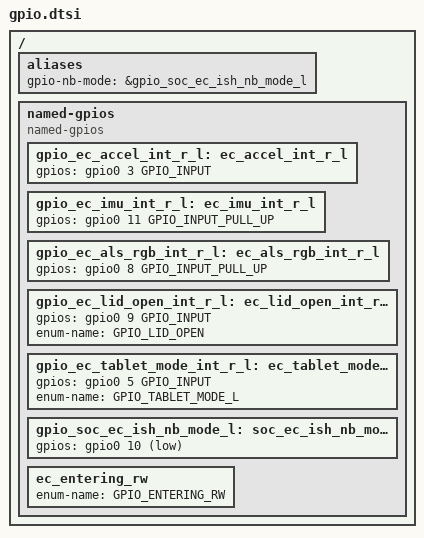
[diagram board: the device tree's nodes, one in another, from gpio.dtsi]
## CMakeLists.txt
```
# Copyright 2023 The ChromiumOS Authors
# Use of this source code is governed by a BSD-style license that can be
# found in the LICENSE file.

zephyr_library_sources("src/board_nb_mode.c")
```

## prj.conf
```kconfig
# Copyright 2023 The ChromiumOS Authors
# Use of this source code is governed by a BSD-style license that can be
# found in the LICENSE file.

# Fix compile issue
CONFIG_CROS_EC_RAM_BASE=0xff216900
CONFIG_CROS_EC_RAM_SIZE=0x00015000
CONFIG_CROS_EC_DATA_RAM_SIZE=0x00010000
CONFIG_CROS_EC_PROGRAM_MEMORY_BASE=0x10090000
CONFIG_CROS_EC_RO_MEM_OFF=0x0
CONFIG_CROS_EC_RO_SIZE=0xb000
CONFIG_CROS_EC_RW_MEM_OFF=0xb000
CONFIG_CROS_EC_RW_SIZE=0x75000

CONFIG_PLATFORM_EC=y
CONFIG_CROS_EC=y
CONFIG_SHIMMED_TASKS=y
CONFIG_SYSCON=y

# Disable default features
CONFIG_BOARD_REX_USBC_CONFIG=n

# Log
CONFIG_LOG=y
CONFIG_LOG_MODE_MINIMAL=y

# Host Interface and  MKBP event
CONFIG_PLATFORM_EC_HOST_INTERFACE_HECI=y
CONFIG_PLATFORM_EC_MKBP_EVENT=y
CONFIG_PLATFORM_EC_MKBP_USE_HECI=y

# ISH BSP config
CONFIG_IPM=y
CONFIG_HECI=y
CONFIG_HOST_SERVICE=y
CONFIG_HECI_INTF_IPM=y
CONFIG_REBOOT=y
CONFIG_SPI=n
CONFIG_GPIO=y

#ISH PM
CONFIG_PM=y
CONFIG_PM_DEVICE=y
CONFIG_PM_DEVICE_RUNTIME=n
CONFIG_GDT_DYNAMIC=y
CONFIG_GDT_RESERVED_NUM_ENTRIES=3
CONFIG_PLATFORM_EC_CONSOLE_CMD_SLEEPMASK=n

# Other
CONFIG_SHELL_PROMPT_UART="ish:~$ "
CONFIG_SHELL_BACKEND_SERIAL_INTERRUPT_DRIVEN=n
CONFIG_SHELL_BACKEND_SERIAL_RX_POLL_PERIOD=60000

# Sensor Console Commands
CONFIG_PLATFORM_EC_CONSOLE_CMD_ACCELS=y
CONFIG_PLATFORM_EC_CONSOLE_CMD_ACCEL_INFO=y
CONFIG_PLATFORM_EC_CONSOLE_CMD_I2C_SPEED=y

# Sensor Feature Configs
CONFIG_PLATFORM_EC_ACCEL_FIFO=y
CONFIG_PLATFORM_EC_DYNAMIC_MOTION_SENSOR_COUNT=y
CONFIG_PLATFORM_EC_LID_ANGLE=y
CONFIG_PLATFORM_EC_LID_ANGLE_UPDATE=y
CONFIG_PLATFORM_EC_SENSOR_TIGHT_TIMESTAMPS=y
CONFIG_PLATFORM_EC_GMR_TABLET_MODE=y
CONFIG_PLATFORM_EC_TABLET_MODE=y
CONFIG_PLATFORM_EC_TABLET_MODE_SWITCH=y
CONFIG_PLATFORM_EC_LID_SWITCH=y

# Sensor Drivers
CONFIG_PLATFORM_EC_ACCEL_LIS2DW12=y

# Notify EC for clamshell/tablet mode change
CONFIG_PLATFORM_EC_EXTERNAL_NOTEBOOK_MODE=y
```

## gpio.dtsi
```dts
/* Copyright 2023 The ChromiumOS Authors
 * Use of this source code is governed by a BSD-style license that can be
 * found in the LICENSE file.
 */
#include <dt-bindings/gpio_defines.h>

/ {

	aliases {
		gpio-nb-mode = &gpio_soc_ec_ish_nb_mode_l;
	};

	named-gpios {
		compatible = "named-gpios";

		gpio_ec_accel_int_r_l: ec_accel_int_r_l {
			gpios = <&gpio0 3 GPIO_INPUT>;
		};
		gpio_ec_imu_int_r_l: ec_imu_int_r_l {
			gpios = <&gpio0 11 GPIO_INPUT_PULL_UP>;
		};
		gpio_ec_als_rgb_int_r_l: ec_als_rgb_int_r_l {
			gpios = <&gpio0 8 GPIO_INPUT_PULL_UP>;
		};
		gpio_ec_lid_open_int_r_l: ec_lid_open_int_r_l {
			gpios = <&gpio0 9 GPIO_INPUT>;
			enum-name = "GPIO_LID_OPEN";
		};
		gpio_ec_tablet_mode_int_r_l: ec_tablet_mode_int_r_l {
			gpios = <&gpio0 5 GPIO_INPUT>;
			enum-name = "GPIO_TABLET_MODE_L";
		};
		gpio_soc_ec_ish_nb_mode_l: soc_ec_ish_nb_mode_l {
			gpios = <&gpio0 10 (GPIO_ACTIVE_LOW | GPIO_OUTPUT_ACTIVE)>;
		};
		ec_entering_rw {
			enum-name = "GPIO_ENTERING_RW";
		};

	};
};
```

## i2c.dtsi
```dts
/* Copyright 2023 The ChromiumOS Authors
 * Use of this source code is governed by a BSD-style license that can be
 * found in the LICENSE file.
 */

/ {
	aliases {
		i2c-0 = &i2c0;
	};

	named-i2c-ports {
		compatible = "named-i2c-ports";
		i2c_ec_i2c_sensor_scl_r: sensor {
			i2c-port = <&i2c0>;
			enum-names = "I2C_PORT_SENSOR";
		};
	};
};

&i2c0 {
	status = "okay";
};
```

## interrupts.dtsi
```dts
/* Copyright 2023 The ChromiumOS Authors
 * Use of this source code is governed by a BSD-style license that can be
 * found in the LICENSE file.
 */

/ {
	gpio-interrupts {
		compatible = "cros-ec,gpio-interrupts";

		int_imu: ec_imu {
			irq-pin = <&gpio_ec_imu_int_r_l>;
			flags = <GPIO_INT_EDGE_FALLING>;
			handler = "lsm6dso_interrupt";
		};
		int_als_rgb: ec_als_rgb {
			irq-pin = <&gpio_ec_als_rgb_int_r_l>;
			flags = <GPIO_INT_EDGE_FALLING>;
			handler = "tcs3400_interrupt";
		};
		int_accel: ec_accel {
			irq-pin = <&gpio_ec_accel_int_r_l>;
			flags = <GPIO_INT_EDGE_FALLING>;
			handler = "lis2dw12_interrupt";
		};
		int_lid_open: ec_lid_open {
			irq-pin = <&gpio_ec_lid_open_int_r_l>;
			flags = <GPIO_INT_EDGE_FALLING>;
			handler = "lid_interrupt";
		};
		int_tablet_mode: ec_tablet_mode {
			irq-pin = <&gpio_ec_tablet_mode_int_r_l>;
			flags = <GPIO_INT_EDGE_FALLING>;
			handler = "gmr_tablet_switch_isr";
		};

	};
};
```

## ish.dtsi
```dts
/* Copyright 2023 The ChromiumOS Authors
 * Use of this source code is governed by a BSD-style license that can be
 * found in the LICENSE file.
 */

/ {
	chosen {
		zephyr,sram = &sram;
		zephyr,console = &uart0;
		zephyr,shell-uart = &uart0;
		zephyr,flash = &sram;
	};
};
```

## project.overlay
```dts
/* Copyright 2023 The ChromiumOS Authors
 * Use of this source code is governed by a BSD-style license that can be
 * found in the LICENSE file.
 */

/* rex-ish project DTSI includes */
#include "gpio.dtsi"
#include "i2c.dtsi"
#include "interrupts.dtsi"
#include "ish.dtsi"
#include <program/rex/motionsense.dtsi>
```

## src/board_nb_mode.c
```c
/* Copyright 2023 The ChromiumOS Authors
 * Use of this source code is governed by a BSD-style license that can be
 * found in the LICENSE file.
 */

#include "hooks.h"
#include "tablet_mode.h"

static void board_nb_mode_change(void)
{
	/*
	 * gpio_soc_ec_ish_nb_mode_l is an active low pin; default level is
	 * low. This pin is an output from SOC (ISH) to EC.
	 *
	 * In this config, ISH runs motion sense task; while EC doesn't.
	 * When ISH motion sense task detects notebook(clamshell)/tablet mode
	 * changes, ISH will notify EC about the change by updating this pin.
	 *
	 * Set this gpio to low if changing to notebook(clamshell) mode;
	 * Set this gpio to high if changing to tablet mode.
	 */
	gpio_pin_set_dt(GPIO_DT_FROM_NODELABEL(gpio_soc_ec_ish_nb_mode_l),
			tablet_get_mode());
}
DECLARE_HOOK(HOOK_TABLET_MODE_CHANGE, board_nb_mode_change, HOOK_PRIO_DEFAULT);
```
